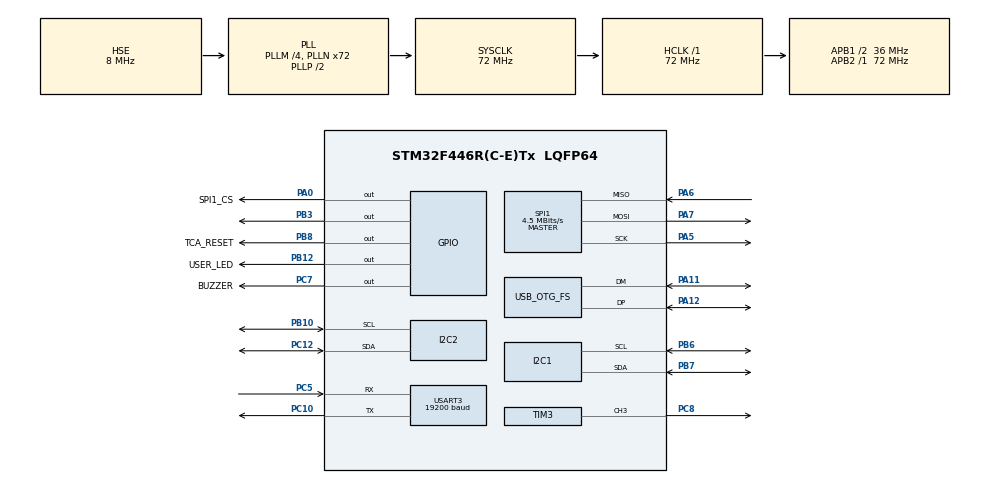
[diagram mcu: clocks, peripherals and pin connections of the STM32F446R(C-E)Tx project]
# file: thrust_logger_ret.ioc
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Dma.Request0=USART3_RX
Dma.USART3_RX.0.Direction=DMA_PERIPH_TO_MEMORY
Dma.USART3_RX.0.FIFOMode=DMA_FIFOMODE_DISABLE
Dma.USART3_RX.0.Instance=DMA1_Stream1
Dma.USART3_RX.0.MemDataAlignment=DMA_MDATAALIGN_BYTE
Dma.USART3_RX.0.MemInc=DMA_MINC_ENABLE
Dma.USART3_RX.0.Mode=DMA_CIRCULAR
Dma.USART3_RX.0.PeriphDataAlignment=DMA_PDATAALIGN_BYTE
Dma.USART3_RX.0.PeriphInc=DMA_PINC_DISABLE
Dma.USART3_RX.0.Priority=DMA_PRIORITY_LOW
FREERTOS.Tasks01=Task_SensorRead,24,512,StartTask_SensorRead,Default,NULL,Dynamic,NULL,NULL;Task_UsbListen,32,512,StartTask_UsbListen,Default,NULL,Dynamic,NULL,NULL
Mcu.Family=STM32F4
Mcu.Name=STM32F446R(C-E)Tx
Mcu.Package=LQFP64
NVIC.DMA1_Stream1_IRQn=true\:5\:0\:false\:false\:true\:true\:false\:true\:true
NVIC.OTG_FS_IRQn=true\:5\:0\:false\:false\:true\:true\:true\:true\:true
NVIC.PriorityGroup=NVIC_PRIORITYGROUP_4
NVIC.TIM1_UP_TIM10_IRQn=true\:15\:0\:false\:false\:true\:false\:false\:true\:true
NVIC.TimeBase=TIM1_UP_TIM10_IRQn
NVIC.TimeBaseIP=TIM1
NVIC.USART3_IRQn=true\:5\:0\:false\:false\:true\:true\:true\:true\:true
PA0-WKUP.GPIO_Label=SPI1_CS
PA0-WKUP.Signal=GPIO_Output
PA11.Mode=Device_Only
PA11.Signal=USB_OTG_FS_DM
PA12.Mode=Device_Only
PA12.Signal=USB_OTG_FS_DP
PA13.Mode=Serial_Wire
PA13.Signal=SYS_JTMS-SWDIO
PA14.Mode=Serial_Wire
PA14.Signal=SYS_JTCK-SWCLK
PA5.Mode=Full_Duplex_Master
PA5.Signal=SPI1_SCK
PA6.Mode=Full_Duplex_Master
PA6.Signal=SPI1_MISO
PA7.Mode=Full_Duplex_Master
PA7.Signal=SPI1_MOSI
PB10.Mode=I2C
PB10.Signal=I2C2_SCL
PB12.GPIO_Label=USER_LED
PB12.PinState=GPIO_PIN_RESET
PB12.Signal=GPIO_Output
PB3.Signal=GPIO_Output
PB6.Mode=I2C
PB6.Signal=I2C1_SCL
PB7.Mode=I2C
PB7.Signal=I2C1_SDA
PB8.GPIO_Label=TCA_RESET
PB8.GPIO_PuPd=GPIO_PULLUP
PB8.PinState=GPIO_PIN_SET
PB8.Signal=GPIO_Output
PC10.GPIO_PuPd=GPIO_NOPULL
PC10.Mode=Asynchronous
PC10.Signal=USART3_TX
PC12.Mode=I2C
PC12.Signal=I2C2_SDA
PC14-OSC32_IN.Mode=LSE-External-Oscillator
PC14-OSC32_IN.Signal=RCC_OSC32_IN
PC15-OSC32_OUT.Mode=LSE-External-Oscillator
PC15-OSC32_OUT.Signal=RCC_OSC32_OUT
PC5.GPIO_PuPd=GPIO_NOPULL
PC5.Mode=Asynchronous
PC5.Signal=USART3_RX
PC7.GPIO_Label=BUZZER
PC7.PinState=GPIO_PIN_SET
PC7.Signal=GPIO_Output
PC8.Signal=S_TIM3_CH3
PH0-OSC_IN.Mode=HSE-External-Oscillator
PH0-OSC_IN.Signal=RCC_OSC_IN
PH1-OSC_OUT.Mode=HSE-External-Oscillator
PH1-OSC_OUT.Signal=RCC_OSC_OUT
ProjectManager.HeapSize=0x200
ProjectManager.StackSize=0x400
ProjectManager.TargetToolchain=STM32CubeIDE
RCC.AHBFreq_Value=72000000
RCC.APB1CLKDivider=RCC_HCLK_DIV2
RCC.APB1Freq_Value=36000000
RCC.APB1TimFreq_Value=72000000
RCC.APB2Freq_Value=72000000
RCC.APB2TimFreq_Value=72000000
RCC.CortexFreq_Value=72000000
RCC.HCLKFreq_Value=72000000
RCC.HSE_VALUE=8000000
RCC.PLLM=4
RCC.PLLN=72
RCC.PLLQ=3
RCC.PLLSourceVirtual=RCC_PLLSOURCE_HSE
RCC.SYSCLKFreq_VALUE=72000000
RCC.SYSCLKSource=RCC_SYSCLKSOURCE_PLLCLK
RCC.USBFreq_Value=48000000
RCC.VCOOutputFreq_Value=144000000
SH.S_TIM3_CH3.0=TIM3_CH3,PWM Generation3 CH3
SPI1.BaudRatePrescaler=SPI_BAUDRATEPRESCALER_16
SPI1.CalculateBaudRate=4.5 MBits/s
SPI1.Direction=SPI_DIRECTION_2LINES
SPI1.Mode=SPI_MODE_MASTER
SPI1.VirtualType=VM_MASTER
TIM3.AutoReloadPreload=TIM_AUTORELOAD_PRELOAD_ENABLE
TIM3.Channel-PWM\ Generation3\ CH3=TIM_CHANNEL_3
TIM3.Period=19999
TIM3.Prescaler=71
TIM3.Pulse-PWM\ Generation3\ CH3=1000
USART3.BaudRate=19200
USART3.Mode=MODE_RX
USART3.OverSampling=UART_OVERSAMPLING_16
USART3.VirtualMode=VM_ASYNC
USB_DEVICE.APP_RX_DATA_SIZE-CDC_FS=2048
USB_DEVICE.APP_TX_DATA_SIZE-CDC_FS=2048
USB_DEVICE.CLASS_NAME_FS=CDC
USB_DEVICE.USBD_SELF_POWERED-CDC_FS=1
USB_DEVICE.VirtualMode-CDC_FS=Cdc
USB_DEVICE.VirtualModeFS=Cdc_FS
USB_OTG_FS.Sof_enable=DISABLE
USB_OTG_FS.VirtualMode=Device_Only
USB_OTG_FS.low_power_enable=DISABLE
USB_OTG_FS.lpm_enable=DISABLE
VP_FREERTOS_VS_CMSIS_V2.Mode=CMSIS_V2
VP_SYS_VS_tim1.Mode=TIM1
VP_TIM3_VS_ClockSourceINT.Mode=Internal
VP_USB_DEVICE_VS_USB_DEVICE_CDC_FS.Mode=CDC_FS
board=custom

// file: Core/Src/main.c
/* USER CODE BEGIN Header */
/* USER CODE END Header */
#include "main.h"
#include "cmsis_os.h"
#include "usb_device.h"

/* USER CODE BEGIN Includes */
#include "application.h"
/* USER CODE END Includes */

I2C_HandleTypeDef hi2c1;
I2C_HandleTypeDef hi2c2;

SPI_HandleTypeDef hspi1;

TIM_HandleTypeDef htim3;

UART_HandleTypeDef huart3;
DMA_HandleTypeDef hdma_usart3_rx;

/* Definitions for Task_SensorRead */
osThreadId_t Task_SensorReadHandle;
const osThreadAttr_t Task_SensorRead_attributes = {
  .name = "Task_SensorRead",
  .stack_size = 512 * 4,
  .priority = (osPriority_t) osPriorityNormal,
};
/* Definitions for Task_UsbListen */
osThreadId_t Task_UsbListenHandle;
const osThreadAttr_t Task_UsbListen_attributes = {
  .name = "Task_UsbListen",
  .stack_size = 512 * 4,
  .priority = (osPriority_t) osPriorityAboveNormal,
};
/* USER CODE BEGIN PV */
INA228_HandleTypeDef powerSensor;
char usb_buffer[128]; // USB üzerinden gönderilecek metni tutacak tampon bellek
/* USER CODE END PV */

void SystemClock_Config(void);
static void MX_GPIO_Init(void);
static void MX_DMA_Init(void);
static void MX_SPI1_Init(void);
static void MX_I2C1_Init(void);
static void MX_I2C2_Init(void);
static void MX_TIM3_Init(void);
static void MX_USART3_UART_Init(void);
void StartTask_SensorRead(void *argument);
void StartTask_UsbListen(void *argument);

int main(void)
{

  /* MCU Configuration--------------------------------------------------------*/

  /* Reset of all peripherals, Initializes the Flash interface and the Systick. */
  HAL_Init();

  /* Configure the system clock */
  SystemClock_Config();

  /* Initialize all configured peripherals */
  MX_GPIO_Init();
  MX_DMA_Init();
  MX_SPI1_Init();
  MX_I2C1_Init();
  MX_I2C2_Init();
  MX_TIM3_Init();
  MX_USART3_UART_Init();
  /* USER CODE BEGIN 2 */
  App_Init();
  /* USER CODE END 2 */

  /* Init scheduler */
  osKernelInitialize();

  /* Create the thread(s) */
  /* creation of Task_SensorRead */
  Task_SensorReadHandle = osThreadNew(StartTask_SensorRead, NULL, &Task_SensorRead_attributes);

  /* creation of Task_UsbListen */
  Task_UsbListenHandle = osThreadNew(StartTask_UsbListen, NULL, &Task_UsbListen_attributes);

  /* Start scheduler */
  osKernelStart();

  /* We should never get here as control is now taken by the scheduler */

  /* Infinite loop */
    while (1)
      {

      }
}

void SystemClock_Config(void)
{
  RCC_OscInitTypeDef RCC_OscInitStruct = {0};
  RCC_ClkInitTypeDef RCC_ClkInitStruct = {0};

  /** Configure the main internal regulator output voltage
  */
  __HAL_RCC_PWR_CLK_ENABLE();
  __HAL_PWR_VOLTAGESCALING_CONFIG(PWR_REGULATOR_VOLTAGE_SCALE3);

  /** Initializes the RCC Oscillators according to the specified parameters
  * in the RCC_OscInitTypeDef structure.
  */
  RCC_OscInitStruct.OscillatorType = RCC_OSCILLATORTYPE_HSE;
  RCC_OscInitStruct.HSEState = RCC_HSE_ON;
  RCC_OscInitStruct.PLL.PLLState = RCC_PLL_ON;
  RCC_OscInitStruct.PLL.PLLSource = RCC_PLLSOURCE_HSE;
  RCC_OscInitStruct.PLL.PLLM = 4;
  RCC_OscInitStruct.PLL.PLLN = 72;
  RCC_OscInitStruct.PLL.PLLP = RCC_PLLP_DIV2;
  RCC_OscInitStruct.PLL.PLLQ = 3;
  RCC_OscInitStruct.PLL.PLLR = 2;
  if (HAL_RCC_OscConfig(&RCC_OscInitStruct) != HAL_OK)
  {
    Error_Handler();
  }

  /** Initializes the CPU, AHB and APB buses clocks
  */
  RCC_ClkInitStruct.ClockType = RCC_CLOCKTYPE_HCLK|RCC_CLOCKTYPE_SYSCLK
                              |RCC_CLOCKTYPE_PCLK1|RCC_CLOCKTYPE_PCLK2;
  RCC_ClkInitStruct.SYSCLKSource = RCC_SYSCLKSOURCE_PLLCLK;
  RCC_ClkInitStruct.AHBCLKDivider = RCC_SYSCLK_DIV1;
  RCC_ClkInitStruct.APB1CLKDivider = RCC_HCLK_DIV2;
  RCC_ClkInitStruct.APB2CLKDivider = RCC_HCLK_DIV1;

  if (HAL_RCC_ClockConfig(&RCC_ClkInitStruct, FLASH_LATENCY_2) != HAL_OK)
  {
    Error_Handler();
  }
}

static void MX_I2C1_Init(void)
{

  hi2c1.Instance = I2C1;
  hi2c1.Init.ClockSpeed = 100000;
  hi2c1.Init.DutyCycle = I2C_DUTYCYCLE_2;
  hi2c1.Init.OwnAddress1 = 0;
  hi2c1.Init.AddressingMode = I2C_ADDRESSINGMODE_7BIT;
  hi2c1.Init.DualAddressMode = I2C_DUALADDRESS_DISABLE;
  hi2c1.Init.OwnAddress2 = 0;
  hi2c1.Init.GeneralCallMode = I2C_GENERALCALL_DISABLE;
  hi2c1.Init.NoStretchMode = I2C_NOSTRETCH_DISABLE;
  if (HAL_I2C_Init(&hi2c1) != HAL_OK)
  {
    Error_Handler();
  }

}

static void MX_I2C2_Init(void)
{

  hi2c2.Instance = I2C2;
  hi2c2.Init.ClockSpeed = 100000;
  hi2c2.Init.DutyCycle = I2C_DUTYCYCLE_2;
  hi2c2.Init.OwnAddress1 = 0;
  hi2c2.Init.AddressingMode = I2C_ADDRESSINGMODE_7BIT;
  hi2c2.Init.DualAddressMode = I2C_DUALADDRESS_DISABLE;
  hi2c2.Init.OwnAddress2 = 0;
  hi2c2.Init.GeneralCallMode = I2C_GENERALCALL_DISABLE;
  hi2c2.Init.NoStretchMode = I2C_NOSTRETCH_DISABLE;
  if (HAL_I2C_Init(&hi2c2) != HAL_OK)
  {
    Error_Handler();
  }

}

static void MX_SPI1_Init(void)
{

  /* SPI1 parameter configuration*/
  hspi1.Instance = SPI1;
  hspi1.Init.Mode = SPI_MODE_MASTER;
  hspi1.Init.Direction = SPI_DIRECTION_2LINES;
  hspi1.Init.DataSize = SPI_DATASIZE_8BIT;
  hspi1.Init.CLKPolarity = SPI_POLARITY_LOW;
  hspi1.Init.CLKPhase = SPI_PHASE_1EDGE;
  hspi1.Init.NSS = SPI_NSS_SOFT;
  hspi1.Init.BaudRatePrescaler = SPI_BAUDRATEPRESCALER_16;
  hspi1.Init.FirstBit = SPI_FIRSTBIT_MSB;
  hspi1.Init.TIMode = SPI_TIMODE_DISABLE;
  hspi1.Init.CRCCalculation = SPI_CRCCALCULATION_DISABLE;
  hspi1.Init.CRCPolynomial = 10;
  if (HAL_SPI_Init(&hspi1) != HAL_OK)
  {
    Error_Handler();
  }

}

static void MX_TIM3_Init(void)
{

  TIM_ClockConfigTypeDef sClockSourceConfig = {0};
  TIM_MasterConfigTypeDef sMasterConfig = {0};
  TIM_OC_InitTypeDef sConfigOC = {0};

  htim3.Instance = TIM3;
  htim3.Init.Prescaler = 71;
  htim3.Init.CounterMode = TIM_COUNTERMODE_UP;
  htim3.Init.Period = 19999;
  htim3.Init.ClockDivision = TIM_CLOCKDIVISION_DIV1;
  htim3.Init.AutoReloadPreload = TIM_AUTORELOAD_PRELOAD_ENABLE;
  if (HAL_TIM_Base_Init(&htim3) != HAL_OK)
  {
    Error_Handler();
  }
  sClockSourceConfig.ClockSource = TIM_CLOCKSOURCE_INTERNAL;
  if (HAL_TIM_ConfigClockSource(&htim3, &sClockSourceConfig) != HAL_OK)
  {
    Error_Handler();
  }
  if (HAL_TIM_PWM_Init(&htim3) != HAL_OK)
  {
    Error_Handler();
  }
  sMasterConfig.MasterOutputTrigger = TIM_TRGO_RESET;
  sMasterConfig.MasterSlaveMode = TIM_MASTERSLAVEMODE_DISABLE;
  if (HAL_TIMEx_MasterConfigSynchronization(&htim3, &sMasterConfig) != HAL_OK)
  {
    Error_Handler();
  }
  sConfigOC.OCMode = TIM_OCMODE_PWM1;
  sConfigOC.Pulse = 1000;
  sConfigOC.OCPolarity = TIM_OCPOLARITY_HIGH;
  sConfigOC.OCFastMode = TIM_OCFAST_DISABLE;
  if (HAL_TIM_PWM_ConfigChannel(&htim3, &sConfigOC, TIM_CHANNEL_3) != HAL_OK)
  {
    Error_Handler();
  }
  HAL_TIM_MspPostInit(&htim3);

}

static void MX_USART3_UART_Init(void)
{

  huart3.Instance = USART3;
  huart3.Init.BaudRate = 19200;
  huart3.Init.WordLength = UART_WORDLENGTH_8B;
  huart3.Init.StopBits = UART_STOPBITS_1;
  huart3.Init.Parity = UART_PARITY_NONE;
  huart3.Init.Mode = UART_MODE_RX;
  huart3.Init.HwFlowCtl = UART_HWCONTROL_NONE;
  huart3.Init.OverSampling = UART_OVERSAMPLING_16;
  if (HAL_UART_Init(&huart3) != HAL_OK)
  {
    Error_Handler();
  }

}

static void MX_DMA_Init(void)
{

  /* DMA controller clock enable */
  __HAL_RCC_DMA1_CLK_ENABLE();

  /* DMA interrupt init */
  /* DMA1_Stream1_IRQn interrupt configuration */
  HAL_NVIC_SetPriority(DMA1_Stream1_IRQn, 5, 0);
  HAL_NVIC_EnableIRQ(DMA1_Stream1_IRQn);

}

static void MX_GPIO_Init(void)
{
  GPIO_InitTypeDef GPIO_InitStruct = {0};

  /* GPIO Ports Clock Enable */
  __HAL_RCC_GPIOC_CLK_ENABLE();
  __HAL_RCC_GPIOH_CLK_ENABLE();
  __HAL_RCC_GPIOA_CLK_ENABLE();
  __HAL_RCC_GPIOB_CLK_ENABLE();

  /*Configure GPIO pin Output Level */
  HAL_GPIO_WritePin(SPI1_CS_GPIO_Port, SPI1_CS_Pin, GPIO_PIN_RESET);

  /*Configure GPIO pin Output Level */
  HAL_GPIO_WritePin(GPIOB, USER_LED_Pin|GPIO_PIN_3, GPIO_PIN_RESET);

  /*Configure GPIO pin Output Level */
  HAL_GPIO_WritePin(BUZZER_GPIO_Port, BUZZER_Pin, GPIO_PIN_SET);

  /*Configure GPIO pin Output Level */
  HAL_GPIO_WritePin(TCA_RESET_GPIO_Port, TCA_RESET_Pin, GPIO_PIN_SET);

  /*Configure GPIO pin : SPI1_CS_Pin */
  GPIO_InitStruct.Pin = SPI1_CS_Pin;
  GPIO_InitStruct.Mode = GPIO_MODE_OUTPUT_PP;
  GPIO_InitStruct.Pull = GPIO_NOPULL;
  GPIO_InitStruct.Speed = GPIO_SPEED_FREQ_LOW;
  HAL_GPIO_Init(SPI1_CS_GPIO_Port, &GPIO_InitStruct);

  /*Configure GPIO pins : USER_LED_Pin PB3 */
  GPIO_InitStruct.Pin = USER_LED_Pin|GPIO_PIN_3;
  GPIO_InitStruct.Mode = GPIO_MODE_OUTPUT_PP;
  GPIO_InitStruct.Pull = GPIO_NOPULL;
  GPIO_InitStruct.Speed = GPIO_SPEED_FREQ_LOW;
  HAL_GPIO_Init(GPIOB, &GPIO_InitStruct);

  /*Configure GPIO pin : BUZZER_Pin */
  GPIO_InitStruct.Pin = BUZZER_Pin;
  GPIO_InitStruct.Mode = GPIO_MODE_OUTPUT_PP;
  GPIO_InitStruct.Pull = GPIO_NOPULL;
  GPIO_InitStruct.Speed = GPIO_SPEED_FREQ_LOW;
  HAL_GPIO_Init(BUZZER_GPIO_Port, &GPIO_InitStruct);

  /*Configure GPIO pin : TCA_RESET_Pin */
  GPIO_InitStruct.Pin = TCA_RESET_Pin;
  GPIO_InitStruct.Mode = GPIO_MODE_OUTPUT_PP;
  GPIO_InitStruct.Pull = GPIO_PULLUP;
  GPIO_InitStruct.Speed = GPIO_SPEED_FREQ_LOW;
  HAL_GPIO_Init(TCA_RESET_GPIO_Port, &GPIO_InitStruct);

}

void StartTask_SensorRead(void *argument)
{
  /* init code for USB_DEVICE */
  MX_USB_DEVICE_Init();
  /* USER CODE BEGIN 5 */
  /* Infinite loop */
  App_TaskSensorRead(argument);
  /* USER CODE END 5 */
}

void StartTask_UsbListen(void *argument)
{
  /* USER CODE BEGIN StartTask_UsbListen */
  /* Infinite loop */

	App_TaskUsbListen(argument);

  /* USER CODE END StartTask_UsbListen */
}

void HAL_TIM_PeriodElapsedCallback(TIM_HandleTypeDef *htim)
{
  if (htim->Instance == TIM1)
  {
    HAL_IncTick();
  }
}

void Error_Handler(void)
{
}
